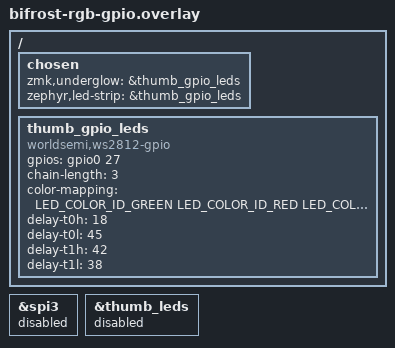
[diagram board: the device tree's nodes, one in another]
/*
 * Copyright (c) 2026 hringdrifi
 * SPDX-License-Identifier: MIT
 */

/* Diagnostic alternative: keep the existing RGB power and data pins. */
&spi3 {
    status = "disabled";
};

&thumb_leds {
    status = "disabled";
};

/ {
    chosen {
        zmk,underglow = &thumb_gpio_leds;
        zephyr,led-strip = &thumb_gpio_leds;
    };

    thumb_gpio_leds: thumb_gpio_leds {
        compatible = "worldsemi,ws2812-gpio";
        gpios = <&gpio0 27 GPIO_ACTIVE_HIGH>;
        chain-length = <3>;
        color-mapping = <LED_COLOR_ID_GREEN LED_COLOR_ID_RED LED_COLOR_ID_BLUE>;
        /* NOP counts for the 64 MHz nRF52840, excluding instruction overhead.
         * This board has no CPU clock-frequency property, so do not use the
         * driver's fallback counts intended for a 16 MHz CPU.
         */
        delay-t0h = <18>;
        delay-t0l = <45>;
        delay-t1h = <42>;
        delay-t1l = <38>;
    };
};
